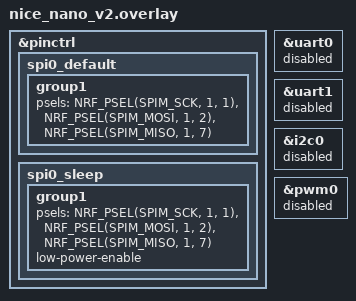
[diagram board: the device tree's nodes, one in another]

&pinctrl {
    spi0_default: spi0_default {
        group1 {
            psels = <NRF_PSEL(SPIM_SCK,  1, 1)>, // SCLK P1.01
                    <NRF_PSEL(SPIM_MOSI, 1, 2)>, // MOSI P1.02
                    <NRF_PSEL(SPIM_MISO, 1, 7)>; // MISO P1.07
        };
    };

    spi0_sleep: spi0_sleep {
        group1 {
            psels = <NRF_PSEL(SPIM_SCK,  1, 1)>, // SCLK P1.01
                    <NRF_PSEL(SPIM_MOSI, 1, 2)>, // MOSI/SDIO P1.02
                    <NRF_PSEL(SPIM_MISO, 1, 7)>; // MISO P1.07
            low-power-enable;
        };
    };


};

&uart0 {
	status = "disabled";
};

&uart1 {
	status = "disabled";
};

&i2c0 {
	status = "disabled";
};

&pwm0 {
	status = "disabled";
};
